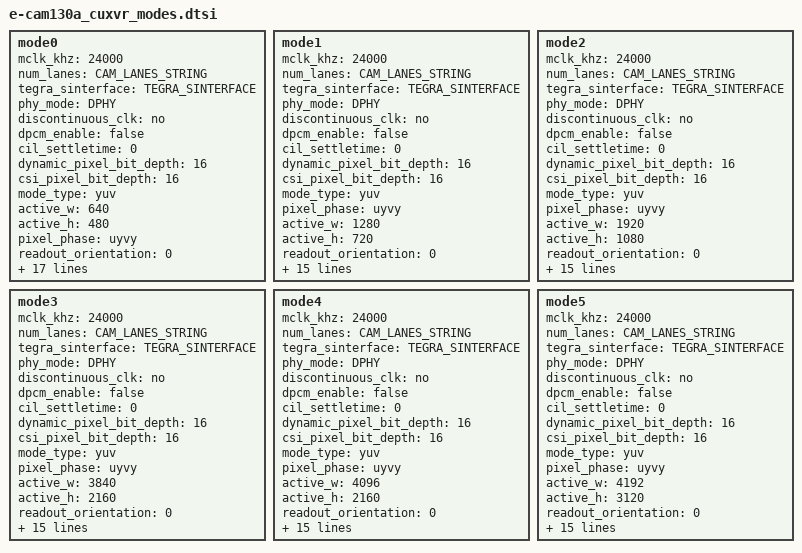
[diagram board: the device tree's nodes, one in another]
/*
 * Copyright (c) 2017-2022, NVIDIA CORPORATION.  All rights reserved.
 *
 * This program is free software; you can redistribute it and/or modify it
 * under the terms and conditions of the GNU General Public License,
 * version 2, as published by the Free Software Foundation.
 *
 * This program is distributed in the hope it will be useful, but WITHOUT
 * ANY WARRANTY; without even the implied warranty of MERCHANTABILITY or
 * FITNESS FOR A PARTICULAR PURPOSE.  See the GNU General Public License for
 * more details.
 *
 * You should have received a copy of the GNU General Public License
 * along with this program.  If not, see <http://www.gnu.org/licenses/>.
 */

mode0 {		// MODE_640X480
	mclk_khz = "24000";
	num_lanes = CAM_LANES_STRING;
	tegra_sinterface = TEGRA_SINTERFACE;
	phy_mode = "DPHY";
	discontinuous_clk = "no";
	dpcm_enable = "false";
	cil_settletime = "0";
	dynamic_pixel_bit_depth = "16";
	csi_pixel_bit_depth = "16";
	mode_type = "yuv";

	active_w = "640";
	active_h = "480";
	pixel_phase = "uyvy";
	readout_orientation = "0";
	deskew_initial_enable = "false";
	line_length = "2000";
	inherent_gain = "1";
	mclk_multiplier = "18";
	pix_clk_hz = "300000000";

	min_gain_val = "0"; /* dB */
	max_gain_val = "48"; /* dB */
	step_gain_val = "1";
	default_gain = "0";
	min_hdr_ratio = "1";
	max_hdr_ratio = "1";
	min_framerate = "1";
	max_framerate = "100";
	step_framerate = "1";
	default_framerate = "30000000";
	min_exp_time = "1";
	max_exp_time = "43000000";
};
mode1 {		// MODE_1280X720
	mclk_khz = "24000";
	num_lanes = CAM_LANES_STRING;
	tegra_sinterface = TEGRA_SINTERFACE;
	phy_mode = "DPHY";
	discontinuous_clk = "no";
	dpcm_enable = "false";
	cil_settletime = "0";
	dynamic_pixel_bit_depth = "16";
	csi_pixel_bit_depth = "16";
	mode_type = "yuv";
	pixel_phase = "uyvy";
	active_w = "1280";
	active_h = "720";
	readout_orientation = "0";
	deskew_initial_enable = "false";
	line_length = "2000";
	inherent_gain = "1";
	mclk_multiplier = "18";
	pix_clk_hz = "350000000";

	min_gain_val = "0"; /* dB */
	max_gain_val = "48"; /* dB */
	default_gain = "0";
	min_hdr_ratio = "1";
	max_hdr_ratio = "1";
	min_framerate = "1";
	max_framerate = "72";
	default_framerate = "30";
	min_exp_time = "30";
	max_exp_time = "660000";
};
mode2 {		// MODE_1920X1080
	mclk_khz = "24000";
	num_lanes = CAM_LANES_STRING;
	tegra_sinterface = TEGRA_SINTERFACE;
	phy_mode = "DPHY";
	discontinuous_clk = "no";
	dpcm_enable = "false";
	cil_settletime = "0";
	dynamic_pixel_bit_depth = "16";
	csi_pixel_bit_depth = "16";
	mode_type = "yuv";
	pixel_phase = "uyvy";

	active_w = "1920";
	active_h = "1080";
	readout_orientation = "0";
	deskew_initial_enable = "false";
	line_length = "2000";
	inherent_gain = "1";
	mclk_multiplier = "18";
	pix_clk_hz = "350000000";

	min_gain_val = "0"; /* dB */
	max_gain_val = "48"; /* dB */
	default_gain = "0";
	min_hdr_ratio = "1";
	max_hdr_ratio = "1";
	min_framerate = "1.5";
	max_framerate = "72";
	default_framerate = "30";
	min_exp_time = "30";
	max_exp_time = "660000";
};
mode3 {		// MODE_3840X2160
	mclk_khz = "24000";
	num_lanes = CAM_LANES_STRING;
	tegra_sinterface = TEGRA_SINTERFACE;
	phy_mode = "DPHY";
	discontinuous_clk = "no";
	dpcm_enable = "false";
	cil_settletime = "0";
	dynamic_pixel_bit_depth = "16";
	csi_pixel_bit_depth = "16";
	mode_type = "yuv";
	pixel_phase = "uyvy";

	active_w = "3840";
	active_h = "2160";
	readout_orientation = "0";
	dskew_initial_enable = "false";
	line_length = "2000";
	inherent_gain = "1";
	mclk_multiplier = "18";
	pix_clk_hz = "350000000";

	min_gain_val = "0"; /* dB */
	max_gain_val = "48"; /* dB */
	default_gain = "0";
	min_hdr_ratio = "1";
	max_hdr_ratio = "1";
	min_framerate = "1";
	max_framerate = "30";
	default_framerate = "30";
	min_exp_time = "30";
	max_exp_time = "660000";
};
mode4 {		// MODE_4096X2160
	mclk_khz = "24000";
	num_lanes = CAM_LANES_STRING;
	tegra_sinterface = TEGRA_SINTERFACE;
	phy_mode = "DPHY";
	discontinuous_clk = "no";
	dpcm_enable = "false";
	cil_settletime = "0";
	dynamic_pixel_bit_depth = "16";
	csi_pixel_bit_depth = "16";
	mode_type = "yuv";
	pixel_phase = "uyvy";

	active_w = "4096";
	active_h = "2160";
	readout_orientation = "0";
	deskew_initial_enable = "false";
	line_length = "2000";
	inherent_gain = "1";
	mclk_multiplier = "18";
	pix_clk_hz = "350000000";

	min_gain_val = "0"; /* dB */
	max_gain_val = "48"; /* dB */
	default_gain = "0";
	min_hdr_ratio = "1";
	max_hdr_ratio = "1";
	min_framerate = "1";
	max_framerate = "19";
	default_framerate = "30";
	min_exp_time = "30";
	max_exp_time = "660000";
};
mode5 {		// MODE_4192X3120
	mclk_khz = "24000";
	num_lanes = CAM_LANES_STRING;
	tegra_sinterface = TEGRA_SINTERFACE;
	phy_mode = "DPHY";
	discontinuous_clk = "no";
	dpcm_enable = "false";
	cil_settletime = "0";
	dynamic_pixel_bit_depth = "16";
	csi_pixel_bit_depth = "16";
	mode_type = "yuv";
	pixel_phase = "uyvy";

	active_w = "4192";
	active_h = "3120";
	readout_orientation = "0";
	deskew_initial_enable = "false";
	line_length = "2000";
	inherent_gain = "1";
	mclk_multiplier = "18";
	pix_clk_hz = "1152000000";

	min_gain_val = "0"; /* dB */
	max_gain_val = "48"; /* dB */
	default_gain = "0";
	min_hdr_ratio = "1";
	max_hdr_ratio = "1";
	min_framerate = "1";
	max_framerate = "19";
	default_framerate = "30";
	min_exp_time = "30";
	max_exp_time = "660000";
};


